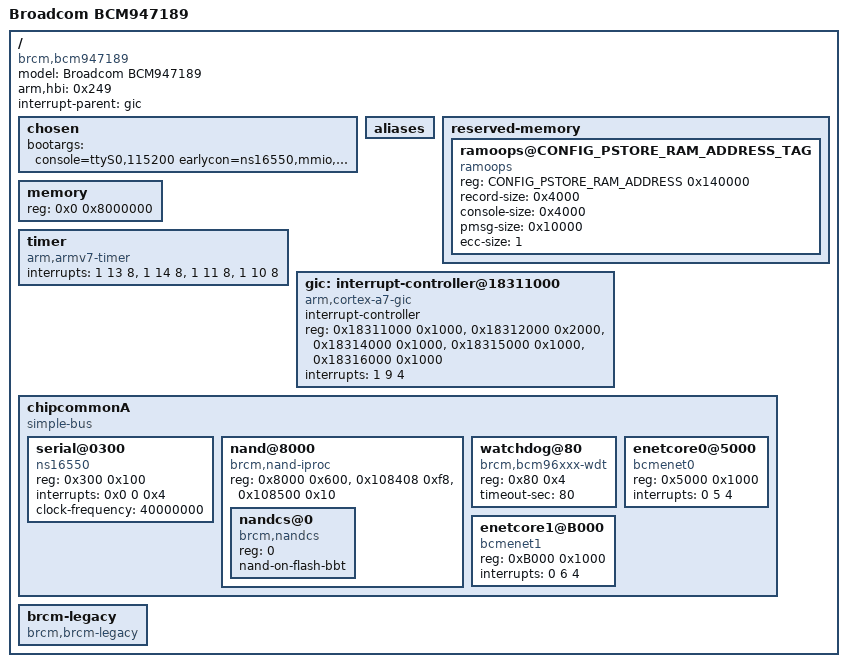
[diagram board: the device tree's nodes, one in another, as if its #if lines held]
#include <dt-bindings/soc/bcm963xx_dt_bindings.h>

/dts-v1/;

/ {
	compatible = "brcm,bcm947189";
	model = "Broadcom BCM947189";
	arm,hbi = <0x249>;
	interrupt-parent = <&gic>;
	#address-cells = <1>;
	#size-cells = <1>;

	chosen {
		bootargs = "console=ttyS0,115200 earlycon=ns16550,mmio,0x18000300,115200n8" ;
	};

	aliases {
	};

#if defined (CONFIG_PSTORE_RAM)

#if !CONFIG_PSTORE_RAM_ADDRESS
/* Default PSTORE address for this platform */
/* Use last 1.25M of 128 MB RAM */
#define CONFIG_PSTORE_RAM_ADDRESS_TAG   07EC0000
#define CONFIG_PSTORE_RAM_ADDRESS     0x07EC0000
#endif

	reserved-memory {
		#address-cells = <1>;
		#size-cells = <1>;
		ranges;

		/* Reserve the region for ramoops, use 1.25M at CONFIG_PSTORE_RAM_ADDRESS */
		ramoops@CONFIG_PSTORE_RAM_ADDRESS_TAG {
			compatible = "ramoops";
			reg = <CONFIG_PSTORE_RAM_ADDRESS 0x140000>;
			record-size = <0x4000>;
			console-size = <0x4000>;
			pmsg-size = <0x10000>;
			ecc-size = <1>;
		};
	};
#endif

	memory {
		device_type = "memory";
		reg = <0x0 0x8000000>;
	};

	timer {
		compatible = "arm,armv7-timer";
		interrupts = <1 13 8>,
			     <1 14 8>,
			     <1 11 8>,
			     <1 10 8>;
	};


	gic: interrupt-controller@18311000 {
		compatible = "arm,cortex-a7-gic";
		#interrupt-cells = <3>;
		#address-cells = <0>;
		interrupt-controller;
		reg = < 0x18311000  0x1000>,
		      < 0x18312000  0x2000>,
		      < 0x18314000  0x1000>,
		      < 0x18315000  0x1000>,
		      < 0x18316000  0x1000>;
		interrupts = <1 9 4>;
	};

	chipcommonA {
		compatible = "simple-bus";
		ranges = <0x0      0x18000000 0x10000
			  0x108000 0x18108000 0x600
			  0x5000   0x18005000 0x1000
			  0xB000   0x1800B000 0x1000>;
		#address-cells = <0x1>;
		#size-cells = <0x1>;

		serial@0300 {
			compatible = "ns16550";
			reg = <0x300 0x100>;
			interrupts = <0x0 0 0x4>;
			clock-frequency = <40000000>;
			status = "okay";
		};

		nand@8000 {
			#address-cells = <1>;
			#size-cells = <0>;
			compatible = "brcm,nand-iproc", "brcm,brcmnand-v6.1";
			reg = <0x8000 0x600>, <0x108408 0xf8>, <0x108500 0x10>;
			reg-names = "nand", "iproc-idm", "iproc-ext";
			status = "okay";

			nandcs@0 {
				compatible = "brcm,nandcs";
				reg = <0>;
				nand-on-flash-bbt;
			};
		};

		watchdog@80 {
			compatible = "brcm,bcm96xxx-wdt";
			reg = <0x80 0x4>;
			timeout-sec = <80>;
		};

#if (CONFIG_BCM_ENET_IMPL == 7)
		enetcore0@5000 {
			compatible = "bcmenet0";
			reg = <0x5000 0x1000>;
			#address-cells = <1>;
			interrupts = <0 5 4>;
		};

		enetcore1@B000 {
			compatible = "bcmenet1";
			reg = <0xB000 0x1000>;
			#address-cells = <1>;
			interrupts = <0 6 4>;
		};
#endif

	};
	brcm-legacy {
		compatible = "brcm,brcm-legacy";
	};
		
};
